# CKGEN_CM2 register map
Vendor: Texas Instruments
Peripheral module from a debugger description file (folder omap4460).
Registers are 32-bit, access per field, reset 0x0 unless marked. A register's access mark holds for its fields unless they carry their own. Offsets are as the file gives them; lines under a group give offsets from that group; [hi:lo] are bit positions; {n}, {i} and the like mark numbered series; 'fields as' and 'values as' point back to an identical list; <NAME> marks a mode.

## CKGEN_CM2
0x00 CM_CLKSEL_MPU_M3_ISS_ROOT — MPU_A3/ISS root clock selection (MPU_A3_ISS_CLK).
  [0] CLKSEL rw — Select the source for the root clock of MPU_A3/ISS
    0=Root clock is sourced from CORE_CLK; 1=Functional clock is sourced from DPLL_PER
0x04 CM_CLKSEL_USB_60MHZ reset 0x1 — Selects the configuration of the divider generating 60MHz clock for USB from the DPLL_USB o/p.
  [0] CLKSEL rw — Select the configuration of the divider
    0=Set the divider in bypass mode to support bypass clock from DPLL_USB to pass through without division; 1=Set the divider to divide the DPLL o/p (480 MHz typical) by 8 to generate 60-MHz clock, to be used for OPP100 and OPP50
0x08 CM_SCALE_FCLK — This register can be used to scale PER_ABE_NC_FCLK, 96M_FCLK, 48M_FCLK, and 64M_FCLK to half their respective typical frequencies.
  [0] SCALE_FCLK rw — Enable or disable the functional clock scaling.
    0=The functional clocks run at their default frequencies; 1=The functional clocks run at half their typical frequencies
0x10 CM_CORE_DVFS_PERF1 — This register allows to system master #1 to specify which level of performance is required from CORE domain (mainly external memory throughput?)
  [7:0] PERF_REQ rw — Current performance request. Unit to be defined by user.
{0xC+4i} CM_CORE_DVFS_PERF{i} (i=2..4) — This register allows to system master #{i} to specify which level of performance is require from CORE domain (mainly external memory throughput?)
  fields as CM_CORE_DVFS_PERF1
0x24 CM_CORE_DVFS_CURRENT — This register hold the current level of performance achievable by the CORE domain, according to the current OPP setting
  [7:0] PERF_CURRENT rw — Current achievable performance level. Unit to be defined by user.
0x28 CM_IVA_DVFS_PERF_DSP — This register allows to specify which level of performance is required from IVA domain for DSP to operate.
  fields as CM_CORE_DVFS_PERF1
0x2C CM_IVA_DVFS_PERF_IVAHD — This register allows to specify which level of performance is required from IVA domain for IVAHD to operate.
  fields as CM_CORE_DVFS_PERF1
0x30 CM_IVA_DVFS_PERF_ABE — This register allows to specify which level of performance is required from IVA domain for ABE to operate.
  fields as CM_CORE_DVFS_PERF1
0x38 CM_IVA_DVFS_CURRENT — This register hold the current level of performance achievable by the IVA domain, according to the current OPP setting
  fields as CM_CORE_DVFS_CURRENT
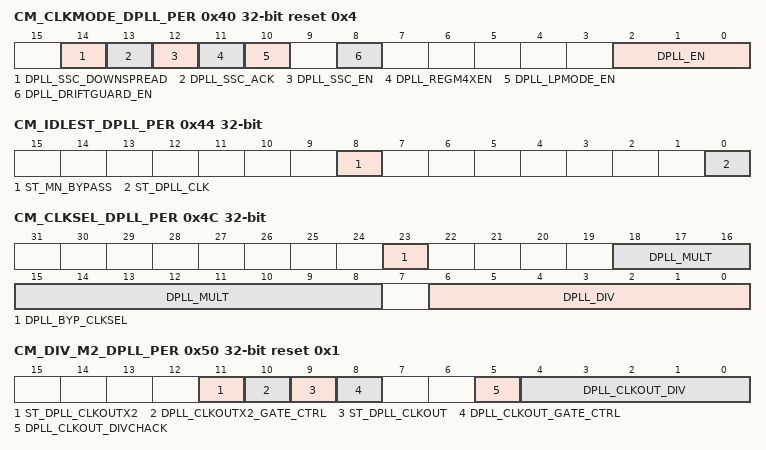
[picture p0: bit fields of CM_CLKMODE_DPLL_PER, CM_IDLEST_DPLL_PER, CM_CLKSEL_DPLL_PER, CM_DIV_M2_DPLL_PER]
0x40 CM_CLKMODE_DPLL_PER reset 0x4 — This register allows controlling the DPLL modes.
  [14] DPLL_SSC_DOWNSPREAD rw — Control if only low frequency spread is required
    0=When SSC is enabled, clock frequency is spread on both sides of the programmed frequency; 1=When SSC is enabled, clock frequency is spread only on the lower side of the programmed frequency
  [13] DPLL_SSC_ACK ro — Acknowledgement from the DPLL regarding start and stop of Spread Spectrum Clocking feature
    0=DPLL_SSC_ACK_0_r (SSC has been turned off on PLL o/ps); 1=DPLL_SSC_ACK_1_r (SSC has been turned on on PLL o/ps)
  [12] DPLL_SSC_EN rw — Enable or disable Spread Spectrum Clocking
    0=SSC disabled; 1=SSC enabled
  [11] DPLL_REGM4XEN ro — Enable the REGM4XEN mode of the DPLL. Please check the DPLL documentation to check when this mode can be enabled.
    0=DPLL_REGM4XEN_0_r (REGM4XEN mode of the DPLL is disabled)
  [10] DPLL_LPMODE_EN rw — Set the DPLL in low-power mode. Check the DPLL documentation to see when this can be enabled.
    0=Low-power mode of the DPLL is disabled; 1=Low-power mode of the DPLL is enabled
  [8] DPLL_DRIFTGUARD_EN rw — This bit allows to enable or disable the automatic recalibration feature of the DPLL. The DPLL will automatically start a recalibration process upon assertion of the DPLL's RECAL flag if this bit is set.
    0=DRIFTGUARD feature is disabled; 1=DRIFTGUARD feature is enabled
  [2:0] DPLL_EN rw — DPLL control. Upon Warm Reset, the PRCM DPLL control state machine updates this register to reflect MN bypass mode.
    4=Put the DPLL in MN bypass mode. The DPLL_MULT register bits are reset to 0 automatically by putting the DPLL in this mode.; 5=Put the DPLL in idle bypass low-power mode; 6=Put the DPLL in idle bypass fast-relock mode; 7=Enables the DPLL in lock mode
0x44 CM_IDLEST_DPLL_PER ro — This register allows monitoring DPLL activity. This register is read only and automatically updated. [warm reset insensitive]
  [8] ST_MN_BYPASS — DPLL MN_BYPASS status
    1=ST_MN_BYPASS_1_r (DPLL is in MN_Bypass); 0=ST_MN_BYPASS_0_r (DPLL is not in MN_Bypass)
  [0] ST_DPLL_CLK — DPLL lock status
    1=ST_DPLL_CLK_1_r (DPLL is LOCKED); 0=ST_DPLL_CLK_0_r (DPLL is either in bypass mode or in stop mode.)
0x48 CM_AUTOIDLE_DPLL_PER — This register provides automatic control over the DPLL activity.
  [2:0] AUTO_DPLL_MODE rw — DPLL automatic control;
    0=DPLL auto control disabled; 1=The DPLL is automatically put in low-power stop mode when its DPLL generated clocks are not required anymore. It is also restarted automatically.; 2=The DPLL is automatically put in fast-relock stop mode when its DPLL generated clocks are not required anymore. It is also restarted automatically.; 5=The DPLL is automatically put in idle bypass low-power mode when its DPLL generated clocks are not required anymore. It is also restarted automatically.; 6=The DPLL is automatically put in idle bypass fast-relock mode when its DPLL generated clocks are not required anymore. It is also restarted automatically.
0x4C CM_CLKSEL_DPLL_PER — This register provides controls over the DPLL.
  [23] DPLL_BYP_CLKSEL rw — Allows control of the BYPASS clock of the PLL and the associated HSDIVIDER. Same as ULOWCLKEN on DPLL. In DPLL Locked mode, 0 - No impact 1 - No impact In DPLL Bypass mode, 0 - CLKINP is selected as the BYPASS clock for CLKOUT/CLKOUTX2 1 - CLKINPULOW is selected as the BYPASS clock for CLKOUT/CLKOUTX2
  [18:8] DPLL_MULT rw — DPLL multiplier factor (2 to 2047). This register is automatically cleared to 0 when the DPLL_EN field in the *CLKMODE_DPLL* register is set to select MN bypass mode. (equal to input M of DPLL; M=2 to 2047 = DPLL multiplies by M).
  [6:0] DPLL_DIV rw — DPLL divider factor (0 to 127) (equal to input N of DPLL; actual division factor is N+1).
0x50 CM_DIV_M2_DPLL_PER reset 0x1 — This register provides controls over the M2 divider of the DPLL.
  [11] ST_DPLL_CLKOUTX2 ro — DPLL CLKOUTX2 status
    0=ST_DPLL_CLKOUTX2_0_r (The clock output is gated); 1=ST_DPLL_CLKOUTX2_1_r (The clock output is enabled)
  [10] DPLL_CLKOUTX2_GATE_CTRL rw — Control gating of DPLL CLKOUTX2
    0=Automatically gate this clock when there is no dependency for it; 1=Force this clock to stay enabled even if there is no request
  [9] ST_DPLL_CLKOUT ro — DPLL CLKOUT status
    0=ST_DPLL_CLKOUT_0_r (The clock output is gated); 1=ST_DPLL_CLKOUT_1_r (The clock output is enabled)
  [8] DPLL_CLKOUT_GATE_CTRL rw — Control gating of DPLL CLKOUT
    values as DPLL_CLKOUTX2_GATE_CTRL
  [5] DPLL_CLKOUT_DIVCHACK ro — Toggle on this status bit after changing DPLL_CLKOUT_DIV indicates that the change in divider value has taken effect.
  [4:0] DPLL_CLKOUT_DIV rw — DPLL post-divider factor, M2, for internal clock generation (1 to 31)
    4=4, to be used for OPP100 and OPP50 (when DPLL_PER is locked at 768 MHz); 8=8, to be used for OPP100 and OPP50 (when DPLL_PER is locked at 1536 MHz)
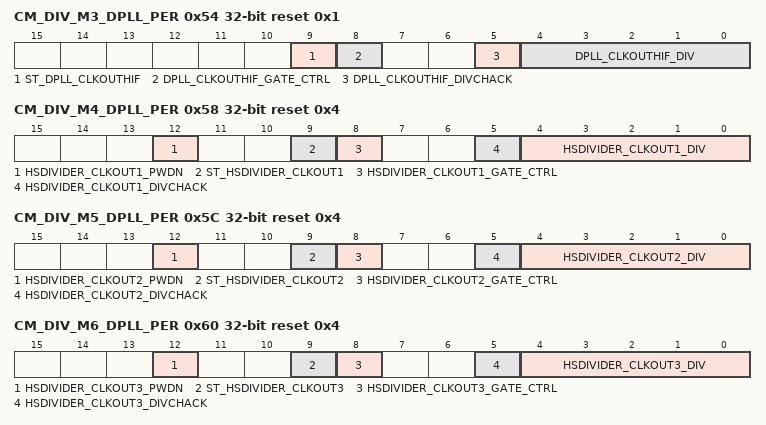
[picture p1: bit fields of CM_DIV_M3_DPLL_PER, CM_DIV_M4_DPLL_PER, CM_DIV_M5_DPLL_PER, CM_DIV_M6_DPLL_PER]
0x54 CM_DIV_M3_DPLL_PER reset 0x1 — This register provides controls over the M3 divider of the DPLL.
  [9] ST_DPLL_CLKOUTHIF ro — DPLL CLKOUTHIF status
    0=ST_DPLL_CLKOUTHIF_0_r (The clock output is gated.); 1=ST_DPLL_CLKOUTHIF_1_r (The clock output is enabled.)
  [8] DPLL_CLKOUTHIF_GATE_CTRL rw — Control gating of DPLL CLKOUTHIF
    0=Gate this clock unconditionally and stop requesting it; 1=Request this clock and un-gate it when available
  [5] DPLL_CLKOUTHIF_DIVCHACK ro — Toggle on this status bit after changing DPLL_CLKOUTHIF_DIV indicates that the change in divider value has taken effect.
  [4:0] DPLL_CLKOUTHIF_DIV rw — DPLL post-divider factor, M3, for internal clock generation (1 to 31). The values listed below (3, 4, 6 and 8) are used for maximum supported frequency at each OPP. Higher dividers (max 31), thus lower frequencies, are also supported.
    3=3, to be used for OPP100 (when DPLL_PER is locked at 768 MHz); 4=4, to be used for OPP50 (when DPLL_PER is locked at 768 MHz); 6=6, to be used for OPP100 (when DPLL_PER is locked at 1536 MHz); 8=8, to be used for OPP50 (when DPLL_PER is locked at 1536 MHz)
0x58 CM_DIV_M4_DPLL_PER reset 0x4 — This register provides controls over the CLKOUT1 o/p of the HSDIVIDER.
  [12] HSDIVIDER_CLKOUT1_PWDN rw — Direct power down control for HSDIVIDER M4 divider and CLKOUT1 output. Power down should be enabled only when clock is first gated.
    0=Divider is powered up; 1=Divider is powered down
  [9] ST_HSDIVIDER_CLKOUT1 ro — HSDIVIDER CLKOUT1 status
    0=ST_HSDIVIDER_CLKOUT1_0_r (The clock output is gated.); 1=ST_HSDIVIDER_CLKOUT1_1_r (The clock output is enabled.)
  [8] HSDIVIDER_CLKOUT1_GATE_CTRL rw — Control gating of HSDIVIDER CLKOUT1
    values as CM_DIV_M2_DPLL_PER.DPLL_CLKOUTX2_GATE_CTRL
  [5] HSDIVIDER_CLKOUT1_DIVCHACK ro — Toggle on this status bit after changing HSDIVIDER_CLKOUT1_DIV indicates that the change in divider value has taken effect.
  [4:0] HSDIVIDER_CLKOUT1_DIV rw — DPLL M4 post-divider factor (1 to 31)
    6=6, to be used for OPP100 and OPP50 (when DPLL_PER is locked at 768 MHz); 12=12, to be used for OPP100 and OPP50 (when DPLL_PER is locked at 1536 MHz)
0x5C CM_DIV_M5_DPLL_PER reset 0x4 — This register provides controls over the CLKOUT2 o/p of the HSDIVIDER.
  [12] HSDIVIDER_CLKOUT2_PWDN rw — Direct power down control for HSDIVIDER M5 divider and CLKOUT2 output. Power down should be enabled only when clock is first gated.
    0=Divider is powered up; 1=Divider is powered down
  [9] ST_HSDIVIDER_CLKOUT2 ro — HSDIVIDER CLKOUT2 status
    0=ST_HSDIVIDER_CLKOUT2_0_r (The clock output is gated.); 1=ST_HSDIVIDER_CLKOUT2_1_r (The clock output is enabled.)
  [8] HSDIVIDER_CLKOUT2_GATE_CTRL rw — Control gating of HSDIVIDER CLKOUT2
    values as CM_DIV_M2_DPLL_PER.DPLL_CLKOUTX2_GATE_CTRL
  [5] HSDIVIDER_CLKOUT2_DIVCHACK ro — Toggle on this status bit after changing HSDIVIDER_CLKOUT2_DIV indicates that the change in divider value has taken effect.
  [4:0] HSDIVIDER_CLKOUT2_DIV rw — DPLL M5 post-divider factor (1 to 31)
    5=5, to be used for OPP100 and OPP50 (when DPLL_PER is locked at 768 MHz); 9=9, to be used for OPP100 and OPP50 (when DPLL_PER is locked at 1536 MHz)
0x60 CM_DIV_M6_DPLL_PER reset 0x4 — This register provides controls over the CLKOUT3 o/p of the HSDIVIDER.
  [12] HSDIVIDER_CLKOUT3_PWDN rw — Direct power down control for HSDIVIDER M6 divider and CLKOUT3 output. Power down should be enabled only when clock is first gated.
    0=Divider is powered up; 1=Divider is powered down
  [9] ST_HSDIVIDER_CLKOUT3 ro — HSDIVIDER CLKOUT3 status
    0=ST_HSDIVIDER_CLKOUT3_0_r (The clock output is gated.); 1=ST_HSDIVIDER_CLKOUT3_1_r (The clock output is enabled.)
  [8] HSDIVIDER_CLKOUT3_GATE_CTRL rw — Control gating of HSDIVIDER CLKOUT3
    values as CM_DIV_M2_DPLL_PER.DPLL_CLKOUTX2_GATE_CTRL
  [5] HSDIVIDER_CLKOUT3_DIVCHACK ro — Toggle on this status bit after changing HSDIVIDER_CLKOUT3_DIV indicates that the change in divider value has taken effect.
  [4:0] HSDIVIDER_CLKOUT3_DIV rw — DPLL M6 post-divider factor (1 to 31)
    2=2, to be used for OPP100 (when DPLL_PER is locked at 768 MHz); 4=4, to be used for OPP100 (when DPLL_PER is locked at 1536 MHz) and for OPP50 (when DPLL_PER is locked at 768 MHz); 8=8, to be used for OPP50 (when DPLL_PER is locked at 1536 MHz)
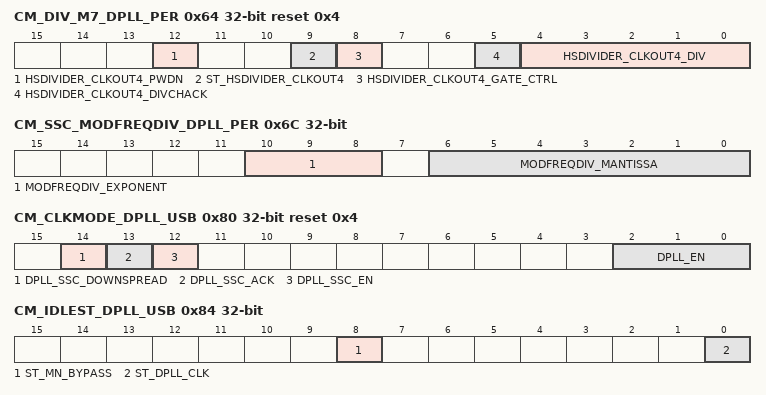
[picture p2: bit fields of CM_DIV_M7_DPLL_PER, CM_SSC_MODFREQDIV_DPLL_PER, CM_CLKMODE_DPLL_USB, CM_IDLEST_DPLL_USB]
0x64 CM_DIV_M7_DPLL_PER reset 0x4 — This register provides controls over the CLKOUT4 o/p of the HSDIVIDER.
  [12] HSDIVIDER_CLKOUT4_PWDN rw — Direct power down control for HSDIVIDER M7 divider and CLKOUT4 output. Power down should be enabled only when clock is first gated.
    0=Divider is powered up; 1=Divider is powered down
  [9] ST_HSDIVIDER_CLKOUT4 ro — HSDIVIDER CLKOUT4 status
    0=ST_HSDIVIDER_CLKOUT4_0_r (The clock output is gated.); 1=ST_HSDIVIDER_CLKOUT4_1_r (The clock output is enabled.)
  [8] HSDIVIDER_CLKOUT4_GATE_CTRL rw — Control gating of HSDIVIDER CLKOUT4
    values as CM_DIV_M2_DPLL_PER.DPLL_CLKOUTX2_GATE_CTRL
  [5] HSDIVIDER_CLKOUT4_DIVCHACK ro — Toggle on this status bit after changing HSDIVIDER_CLKOUT4_DIV indicates that the change in divider value has taken effect.
  [4:0] HSDIVIDER_CLKOUT4_DIV rw — DPLL M7 post-divider factor (1 to 31)
    3=3, to be used for OPP100 (when DPLL_PER is locked at 768 MHz); 5=5, to be used for OPP100 (when DPLL_PER is locked at 1536 MHz); 6=6, to be used for OPP50 (when DPLL_PER is locked at 768 MHz); 10=10, to be used for OPP50 (when DPLL_PER is locked at 1536 MHz)
0x68 CM_SSC_DELTAMSTEP_DPLL_PER — Control the DeltaMStep parameter for Spread Spectrum Clocking. [warm reset insensitive]
  [19:0] DELTAMSTEP rw — DeltaMStep is split into fractional and integer part. For Triangular Spread Spectrum: [19:18] for integer part, [17:0] for fractional part For Square Wave Spread Spectrum [19:14] for integer part, [13:0] for fractional part
0x6C CM_SSC_MODFREQDIV_DPLL_PER — Control the Modulation Frequency (Fm) for Spread Spectrum. [warm reset insensitive]
  [10:8] MODFREQDIV_EXPONENT rw — Set the Exponent component of MODFREQDIV factor
  [6:0] MODFREQDIV_MANTISSA rw — Set the Mantissa component of MODFREQDIV factor
0x80 CM_CLKMODE_DPLL_USB reset 0x4 — This register allows controlling the DPLL modes.
  [14] DPLL_SSC_DOWNSPREAD rw — Control if only low frequency spread is required
    values as CM_CLKMODE_DPLL_PER.DPLL_SSC_DOWNSPREAD
  [13] DPLL_SSC_ACK ro — Acknowledgement from the DPLL regarding start and stop of Spread Spectrum Clocking feature
    values as CM_CLKMODE_DPLL_PER.DPLL_SSC_ACK
  [12] DPLL_SSC_EN rw — Enable or disable Spread Spectrum Clocking
    0=SSC disabled; 1=SSC enabled
  [2:0] DPLL_EN rw — DPLL control. Upon Warm Reset, the PRCM DPLL control state machine updates this register to reflect DPLL low-power stop mode.
    1=Put the DPLL in low-power stop mode; 2=Reserved2; 4=Put the DPLL in MN bypass mode. The DPLL_MULT register bits are reset to 0 automatically by putting the DPLL in this mode.; 5=Put the DPLL in idle bypass low-power mode; 7=Enables the DPLL in lock mode
0x84 CM_IDLEST_DPLL_USB ro — This register allows monitoring DPLL activity. This register is read only and automatically updated. [warm reset insensitive]
  fields as CM_IDLEST_DPLL_PER
0x88 CM_AUTOIDLE_DPLL_USB — This register provides automatic control over the DPLL activity.
  [2:0] AUTO_DPLL_MODE rw — DPLL automatic control;
    0=DPLL auto control disabled; 1=The DPLL is automatically put in low-power stop mode when its DPLL generated clocks are not required anymore. It is also restarted automatically.; 5=The DPLL is automatically put in idle bypass low-power mode when its DPLL generated clocks are not required anymore. It is also restarted automatically.
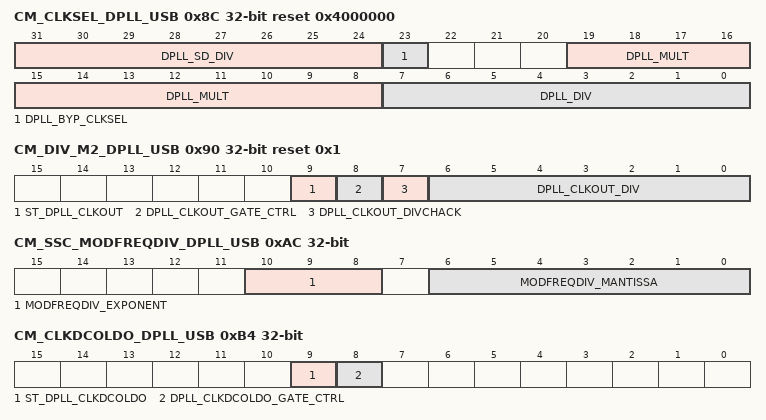
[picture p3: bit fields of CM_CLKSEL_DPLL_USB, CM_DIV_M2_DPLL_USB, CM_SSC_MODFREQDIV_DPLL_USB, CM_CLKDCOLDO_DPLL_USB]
0x8C CM_CLKSEL_DPLL_USB reset 0x4000000 — This register provides controls over the DPLL.
  [31:24] DPLL_SD_DIV rw — Sigma-Delta divider select (2-255). This factor must be set by s/w to ensure optimum jitter performance. DPLL_SD_DIV = CEILING ([DPLL_MULT/(DPLL_DIV+1)] * CLKINP / 250), where CLKINP is the input clock of the DPLL in MHz). Must be set with M and N factors, and must not be changed once DPLL is locked.
  [23] DPLL_BYP_CLKSEL rw — Allows control of the BYPASS clock of the PLL and the associated HSDIVIDER. Same as ULOWCLKEN on DPLL. In DPLL locked mode, 0 - No impact 1 - No impact In DPLL bypass mode, 0 - CLKINP is selected as the BYPASS clock for CLKOUT 1 - CLKINPULOW is selected as the BYPASS clock for CLKOUT
  [19:8] DPLL_MULT rw — DPLL multiplier factor (2 to 4095). This register is automatically cleared to 0 when the DPLL_EN field in the *CLKMODE_DPLL* register is set to select MN bypass mode. (equal to input M of DPLL; M=2 to 4095 = DPLL multiplies by M).
  [7:0] DPLL_DIV rw — DPLL divider factor (0 to 255) (equal to input N of DPLL; actual division factor is N+1).
0x90 CM_DIV_M2_DPLL_USB reset 0x1 — This register provides controls over the M2 divider of the DPLL.
  [9] ST_DPLL_CLKOUT ro — DPLL CLKOUT status
    0=ST_DPLL_CLKOUT_0_r (The clock output is gated.); 1=ST_DPLL_CLKOUT_1_r (The clock output is enabled.)
  [8] DPLL_CLKOUT_GATE_CTRL rw — Control gating of DPLL CLKOUT
    values as CM_DIV_M2_DPLL_PER.DPLL_CLKOUTX2_GATE_CTRL
  [7] DPLL_CLKOUT_DIVCHACK ro — Toggle on this status bit after changing DPLL_CLKOUT_DIV indicates that the change in divider value has taken effect.
  [6:0] DPLL_CLKOUT_DIV rw — DPLL post-divider factor, M2, for internal clock generation (1 to 127)
    2=2, to be used for OPP100 and OPP50
0xA8 CM_SSC_DELTAMSTEP_DPLL_USB — Control the DeltaMStep parameter for Spread Spectrum Clocking. [warm reset insensitive]
  [20:0] DELTAMSTEP rw — DeltaMStep is split into fractional and integer part. For Triangular Spread Spectrum: [20:18] for integer part, [17:0] for fractional part For Square Wave Spread Spectrum [19:14] for integer part, [13:0] for fractional part
0xAC CM_SSC_MODFREQDIV_DPLL_USB — Control the Modulation Frequency (Fm) for Spread Spectrum. [warm reset insensitive]
  fields as CM_SSC_MODFREQDIV_DPLL_PER
0xB4 CM_CLKDCOLDO_DPLL_USB — This register provides controls over the CLKDCOLDO output of the DPLL.
  [9] ST_DPLL_CLKDCOLDO ro — DPLL CLKDCOLDO status
    0=ST_DPLL_CLKDCOLDO_0_r (The clock output is gated); 1=ST_DPLL_CLKDCOLDO_1_r (The clock output is enabled)
  [8] DPLL_CLKDCOLDO_GATE_CTRL rw — Control gating of DPLL CLKDCOLDO
    0=Automatically gate this clock when there is no request for it; 1=Force this clock to stay enabled even if there is no request
